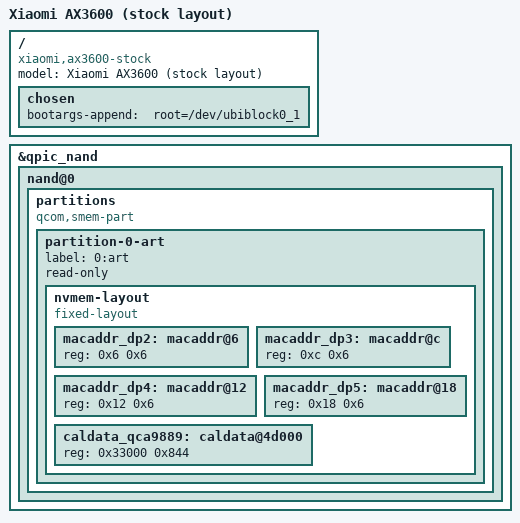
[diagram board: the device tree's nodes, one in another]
// SPDX-License-Identifier: GPL-2.0-or-later OR MIT

#include "ipq8071-ax3600.dts"

/ {
	model = "Xiaomi AX3600 (stock layout)";
	compatible = "xiaomi,ax3600-stock", "qcom,ipq8074";

	chosen {
		bootargs-append = " root=/dev/ubiblock0_1";
	};
};

&qpic_nand {
	/delete-node/ partitions;

	nand@0 {
		/delete-node/ partitions;

		partitions {
			compatible = "qcom,smem-part";

			partition-0-art {
				label = "0:art";
				read-only;

				nvmem-layout {
					compatible = "fixed-layout";
					#address-cells = <1>;
					#size-cells = <1>;

					macaddr_dp2: macaddr@6 {
						reg = <0x6 0x6>;
					};

					macaddr_dp3: macaddr@c {
						reg = <0xc 0x6>;
					};

					macaddr_dp4: macaddr@12 {
						reg = <0x12 0x6>;
					};

					macaddr_dp5: macaddr@18 {
						reg = <0x18 0x6>;
					};

					caldata_qca9889: caldata@4d000 {
						reg = <0x33000 0x844>;
					};
				};
			};
		};
	};
};
